VERSION ""

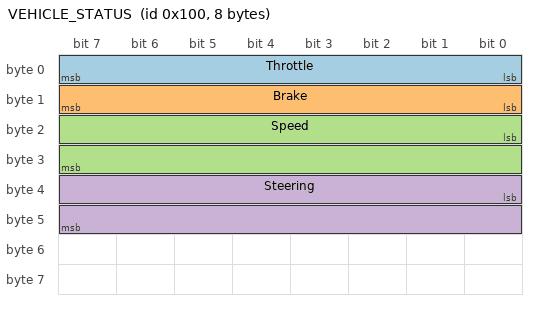
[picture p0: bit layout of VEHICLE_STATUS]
BO_ 256 VEHICLE_STATUS: 8 Vector__XXX
 SG_ Throttle : 0|8@1+ (0.4,0) [0|100] "%" Vector__XXX
 SG_ Brake    : 8|8@1+ (0.4,0) [0|100] "%" Vector__XXX
 SG_ Speed    : 16|16@1+ (0.01,0) [0|250] "km/h" Vector__XXX
 SG_ Steering : 32|16@1- (0.1,0) [-720|720] "deg" Vector_XXX

BO_ 257 TURN_SIGNALS: 1 Vector__XXX
 SG_ Left  : 0|1@1+ (1,0) [0|1] "" Vector__XXX
 SG_ Right : 1|1@1+ (1,0) [0|1] "" Vector__XXX

BO_ 258 TIME_STATUS: 4 Vector__XXX
 SG_ Timestamp : 0|32@1+ (0.001,0) [0|4294967] "s" Vector__XXX
